# GD32E53x register map
File version: 1.0
CPU: CM33 r0p4, little endian, MPU, FPU, 4 interrupt priority bits
Registers are 32-bit, read-write, reset 0x0 unless marked. A register's access mark holds for its fields unless they carry their own. Offsets are from the block's base; [hi:lo] are bit positions; {n}, {i} and the like mark numbered series.

## RCU — Reset and clock unit
Base 0x40021000
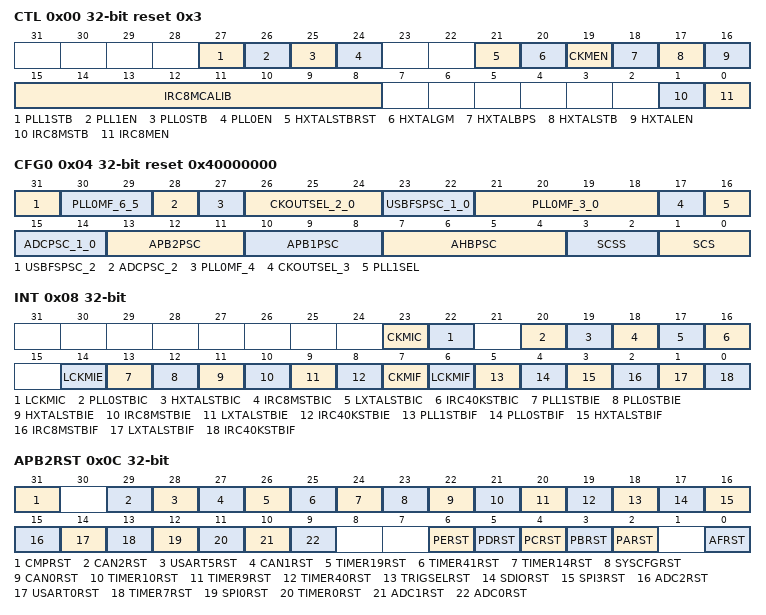
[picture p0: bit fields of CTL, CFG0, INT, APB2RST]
0x00 CTL access per field reset 0x3 — Control register
  [27] PLL1STB ro — PLL1 clock stabilization flag
  [26] PLL1EN rw — PLL1 enable
  [25] PLL0STB ro — PLL0 clock stabilization flag
  [24] PLL0EN rw — PLL0 enable
  [21] HXTALSTBRST rw — Reset HXTALSTB bit.
  [20] HXTALGM rw — HXTAL gm control
  [19] CKMEN rw — HXTAL clock monitor enable
  [18] HXTALBPS rw — High speed crystal oscillator (HXTAL) clock bypass mode enable
  [17] HXTALSTB ro — High speed crystal oscillator (HXTAL) clock stabilization flag
  [16] HXTALEN rw — High speed crystal oscillator (HXTAL) Enable
  [15:8] IRC8MCALIB ro — Internal 8MHz RC oscillator calibration value register
  [1] IRC8MSTB ro — IRC8M internal 8MHz RC oscillator stabilization flag
  [0] IRC8MEN rw — Internal 8MHz RC oscillator enable
0x04 CFG0 access per field reset 0x40000000 — Clock configuration register 0
  [31] USBFSPSC_2 rw — Bit 2 of USBFSPSC
  [30:29] PLL0MF_6_5 rw — Bit 6 and Bit 5 of PLL0MF
  [28] ADCPSC_2 rw — Bit 2 of ADCPSC
  [27] PLL0MF_4 rw — Bit 4 of PLL0MF
  [26:24] CKOUTSEL_2_0 rw — CKOUT clock source selection
  [23:22] USBFSPSC_1_0 rw — USBFS clock prescaler selection
  [21:18] PLL0MF_3_0 rw — The PLL0 clock multiplication factor
  [17] CKOUTSEL_3 rw — Bit 3 of CKOUTSEL
  [16] PLL1SEL rw — PLL1 clock source selection
  [15:14] ADCPSC_1_0 rw — ADC clock prescaler selection
  [13:11] APB2PSC rw — APB2 prescaler selection
  [10:8] APB1PSC rw — APB1 prescaler selection
  [7:4] AHBPSC rw — AHB prescaler selection
  [3:2] SCSS ro — System clock switch status
  [1:0] SCS rw — System clock switch
0x08 INT access per field — Clock interrupt register
  [23] CKMIC wo — HXTAL clock stuck interrupt clear
  [22] LCKMIC wo — LXTAL clock stuck interrupt clear
  [20] PLL0STBIC wo — PLL0 stabilization interrupt clear
  [19] HXTALSTBIC wo — HXTAL stabilization interrupt clear
  [18] IRC8MSTBIC wo — IRC8M stabilization interrupt clear
  [17] LXTALSTBIC wo — LXTAL stabilization interrupt clear
  [16] IRC40KSTBIC wo — IRC40K stabilization interrupt clear
  [14] LCKMIE rw — LXTAL clock stuck interrupt enable
  [13] PLL1STBIE rw — PLL1 stabilization interrupt enable
  [12] PLL0STBIE rw — PLL0 stabilization interrupt enable
  [11] HXTALSTBIE rw — HXTAL stabilization interrupt enable
  [10] IRC8MSTBIE rw — IRC8M stabilization interrupt enable
  [9] LXTALSTBIE rw — LXTAL stabilization interrupt enable
  [8] IRC40KSTBIE rw — IRC40K stabilization interrupt enable
  [7] CKMIF ro — HXTAL clock stuck interrupt flag
  [6] LCKMIF ro — LXTAL clock stuck interrupt flag
  [5] PLL1STBIF ro — PLL1 stabilization interrupt flag
  [4] PLL0STBIF ro — PLL0 stabilization interrupt flag
  [3] HXTALSTBIF ro — HXTAL stabilization interrupt flag
  [2] IRC8MSTBIF ro — IRC8M stabilization interrupt flag
  [1] LXTALSTBIF ro — LXTAL stabilization interrupt flag
  [0] IRC40KSTBIF ro — IRC40K stabilization interrupt flag
0x0C APB2RST — APB2 reset register
  [31] CMPRST — CMP reset
  [29] CAN2RST — CAN2 reset
  [28] USART5RST — USART5 reset
  [27] CAN1RST — CAN1 reset
  [26] TIMER19RST — TIMER19 reset
  [25] TIMER41RST — TIMER41 reset
  [24] TIMER14RST — TIMER14 reset
  [23] SYSCFGRST — SYSCFG reset
  [22] CAN0RST — CAN0 reset
  [21] TIMER10RST — TIMER10 reset
  [20] TIMER9RST — TIMER9 reset
  [19] TIMER40RST — TIMER40 reset
  [18] TRIGSELRST — TRIGSEL reset
  [17] SDIORST — SDIO reset
  [16] SPI3RST — SPI3 reset
  [15] ADC2RST — ADC2 reset
  [14] USART0RST — USART0 reset
  [13] TIMER7RST — TIMER7 reset
  [12] SPI0RST — SPI0 reset
  [11] TIMER0RST — TIMER0 reset
  [10] ADC1RST — ADC1 reset
  [9] ADC0RST — ADC0 reset
  [6] PERST — GPIOE reset
  [5] PDRST — GPIOD reset
  [4] PCRST — GPIOC reset
  [3] PBRST — GPIOB reset
  [2] PARST — GPIOA reset
  [0] AFRST — AFIO reset
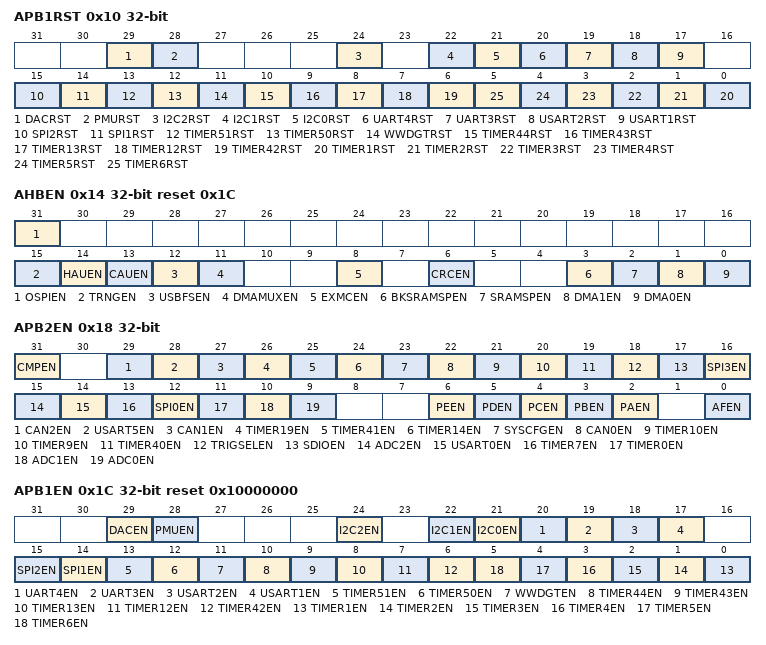
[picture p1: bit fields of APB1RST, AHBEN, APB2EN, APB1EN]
0x10 APB1RST — APB1 reset register
  [29] DACRST — DAC reset
  [28] PMURST — PMU reset
  [24] I2C2RST — I2C2 reset
  [22] I2C1RST — I2C1 reset
  [21] I2C0RST — I2C0 reset
  [20] UART4RST — UART4 reset
  [19] UART3RST — UART3 reset
  [18] USART2RST — USART2 reset
  [17] USART1RST — USART1 reset
  [15] SPI2RST — SPI2 reset
  [14] SPI1RST — SPI1 reset
  [13] TIMER51RST — TIMER51 reset
  [12] TIMER50RST — TIMER50 reset
  [11] WWDGTRST — WWDGT reset
  [10] TIMER44RST — TIMER44 reset
  [9] TIMER43RST — TIMER43 reset
  [8] TIMER13RST — TIMER13 reset
  [7] TIMER12RST — TIMER12 reset
  [6] TIMER42RST — TIMER42 reset
  [n-1] TIMER{n}RST (n=1..6) — TIMER{n} reset
0x14 AHBEN reset 0x1C — AHB enable register
  [31] OSPIEN — OSPI clock enable
  [15] TRNGEN — TRNG clock enable
  [14] HAUEN — HAU clock enable
  [13] CAUEN — CAU clock enable
  [12] USBFSEN — USBFS clock enable
  [11] DMAMUXEN — DMAMUX clock enable
  [8] EXMCEN — EXMC clock enable
  [6] CRCEN — CRC clock enable
  [3] BKSRAMSPEN — Back up SRAM clock enable when sleep mode
  [2] SRAMSPEN — SRAM interface clock enable when sleep mode
  [1] DMA1EN — DMA1 clock enable
  [0] DMA0EN — DMA0 clock enable
0x18 APB2EN — APB2 enable register
  [31] CMPEN — CMP clock enable
  [29] CAN2EN — CAN2 clock enable
  [28] USART5EN — USART5 clock enable
  [27] CAN1EN — CAN1 clock enable
  [26] TIMER19EN — TIMER19 clock enable
  [25] TIMER41EN — TIMER41 clock enable
  [24] TIMER14EN — TIMER14 clock enable
  [23] SYSCFGEN — SYSCFG clock enable
  [22] CAN0EN — CAN0 clock enable
  [21] TIMER10EN — TIMER10 clock enable
  [20] TIMER9EN — TIMER9 clock enable
  [19] TIMER40EN — TIMER40 clock enable
  [18] TRIGSELEN — TRIGSEL clock enable
  [17] SDIOEN — SDIO clock enable
  [16] SPI3EN — SPI3 clock enable
  [15] ADC2EN — ADC2 clock enable
  [14] USART0EN — USART0 clock enable
  [13] TIMER7EN — TIMER7 clock enable
  [12] SPI0EN — SPI0 clock enable
  [11] TIMER0EN — TIMER0 clock enable
  [10] ADC1EN — ADC1 clock enable
  [9] ADC0EN — ADC0 clock enable
  [6] PEEN — GPIO port E clock enable
  [5] PDEN — GPIO port D clock enable
  [4] PCEN — GPIO port C clock enable
  [3] PBEN — GPIO port B clock enable
  [2] PAEN — GPIO port A clock enable
  [0] AFEN — Alternate function IO clock enable
0x1C APB1EN reset 0x10000000 — APB1 enable register
  [29] DACEN — DAC clock enable
  [28] PMUEN — PMU clock enable
  [24] I2C2EN — I2C2 clock enable
  [22] I2C1EN — I2C1 clock enable
  [21] I2C0EN — I2C0 clock enable
  [20] UART4EN — UART4 clock enable
  [19] UART3EN — UART3 clock enable
  [18] USART2EN — USART2 clock enable
  [17] USART1EN — USART1 clock enable
  [15] SPI2EN — SPI2 clock enable
  [14] SPI1EN — SPI1 clock enable
  [13] TIMER51EN — TIMER51 clock enable
  [12] TIMER50EN — TIMER50 clock enable
  [11] WWDGTEN — WWDGT clock enable
  [10] TIMER44EN — TIMER44 clock enable
  [9] TIMER43EN — TIMER43 clock enable
  [8] TIMER13EN — TIMER13 clock enable
  [7] TIMER12EN — TIMER12 clock enable
  [6] TIMER42EN — TIMER42 clock enable
  [n-1] TIMER{n}EN (n=1..6) — TIMER{n} clock enable
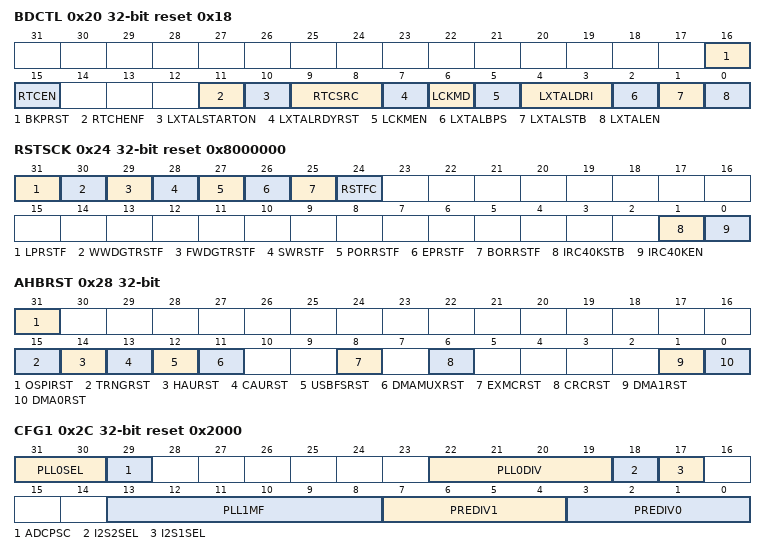
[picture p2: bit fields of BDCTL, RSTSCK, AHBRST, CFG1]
0x20 BDCTL access per field reset 0x18 — Backup domain control register
  [16] BKPRST rw — Backup domain reset
  [15] RTCEN rw — RTC clock enable
  [11] RTCHENF ro — RTC high frequency clock enable flag
  [10] LXTALSTARTON rw — LXTAL start circuit on control
  [9:8] RTCSRC rw — RTC clock entry selection
  [7] LXTALRDYRST rw — LXTAL ready reset
  [6] LCKMD ro — LXTAL clock failure detection
  [5] LCKMEN rw — LXTAL clock monitor enable
  [4:3] LXTALDRI rw — LXTAL drive capability
  [2] LXTALBPS rw — LXTAL bypass mode enable
  [1] LXTALSTB ro — Low speed crystal oscillator stabilization flag
  [0] LXTALEN rw — LXTAL enable
0x24 RSTSCK access per field reset 0x8000000 — Reset source/clock register
  [31] LPRSTF ro — Low-power reset flag
  [30] WWDGTRSTF ro — Window watchdog timer reset flag
  [29] FWDGTRSTF ro — Free watchdog timer reset flag
  [28] SWRSTF ro — Software reset flag
  [27] PORRSTF ro — Power reset flag
  [26] EPRSTF ro — External pin reset flag
  [25] BORRSTF ro — BOR reset flag
  [24] RSTFC rw — Reset flag clear
  [1] IRC40KSTB ro — IRC40K stabilization flag
  [0] IRC40KEN rw — IRC40K enable
0x28 AHBRST — AHB reset register
  [31] OSPIRST — OSPI reset
  [15] TRNGRST — TRNG reset
  [14] HAURST — HAU reset
  [13] CAURST — CAU reset
  [12] USBFSRST — USBFS reset
  [11] DMAMUXRST — DMAMUX reset
  [8] EXMCRST — EXMC reset
  [6] CRCRST — CRC reset
  [1] DMA1RST — DMA0 reset
  [0] DMA0RST — DMA1 reset
0x2C CFG1 reset 0x2000 — Clock configuration register 1
  [31:30] PLL0SEL — PLL0 clock source selection
  [29] ADCPSC — Bit 4 of ADCPSC
  [22:19] PLL0DIV — PLL0 divider
  [18] I2S2SEL — I2S2 Clock Source Selection
  [17] I2S1SEL — I2S1 Clock Source Selection
  [13:8] PLL1MF — The PLL1 clock multiplication factor
  [7:4] PREDIV1 — PREDIV1 division factor.
  [3:0] PREDIV0 — PREDIV0 division factor.
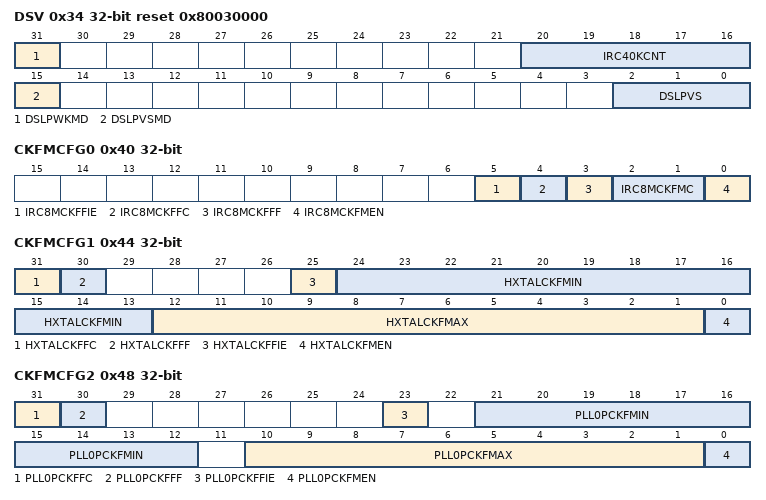
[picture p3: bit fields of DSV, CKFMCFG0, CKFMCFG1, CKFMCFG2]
0x34 DSV reset 0x80030000 — Deep-sleep mode voltage register
  [31] DSLPWKMD — Deepsleep wake-up method.
  [20:16] IRC40KCNT — After DeepSleep wake-up, the startup waiting time is forced to be configured as 3
  [15] DSLPVSMD — Deep sleep mode voltage selection mode
  [2:0] DSLPVS — Deep sleep mode voltage selection
0x40 CKFMCFG0 access per field — Clock frequency monitor configuration register 0
  [5] IRC8MCKFFIE rw — IRC8M clock frequency failure interrupt enable
  [4] IRC8MCKFFC wo — IRC8M clock frequency failure flag clear
  [3] IRC8MCKFFF ro — IRC8M clock frequency failure flag
  [2:1] IRC8MCKFMC rw — IRC8M clock frequency monitor configuration
  [0] IRC8MCKFMEN rw — IRC8M clock frequency monitor enable
0x44 CKFMCFG1 access per field — Clock frequency monitor configuration register 1
  [31] HXTALCKFFC wo — HXTAL clock frequency failure flag clear
  [30] HXTALCKFFF ro — HXTAL clock frequency failure flag
  [25] HXTALCKFFIE rw — HXTAL clock frequency failure interrupt enable
  [24:13] HXTALCKFMIN rw — HXTAL clock frequency monitor configuration minimum value
  [12:1] HXTALCKFMAX rw — HXTAL clock frequency monitor configuration maximum value
  [0] HXTALCKFMEN rw — HXTAL clock frequency monitor enable
0x48 CKFMCFG2 access per field — Clock frequency monitor configuration register 2
  [31] PLL0PCKFFC wo — PLL0P clock frequency failure flag clear
  [30] PLL0PCKFFF ro — PLL0P clock frequency failure flag
  [23] PLL0PCKFFIE rw — PLL0P clock frequency failure interrupt enable
  [21:12] PLL0PCKFMIN rw — PLL0P clock frequency monitor configuration minimum value
  [10:1] PLL0PCKFMAX rw — PLL0P clock frequency monitor configuration maximum value
  [0] PLL0PCKFMEN rw — PLL0P clock frequency monitor enable
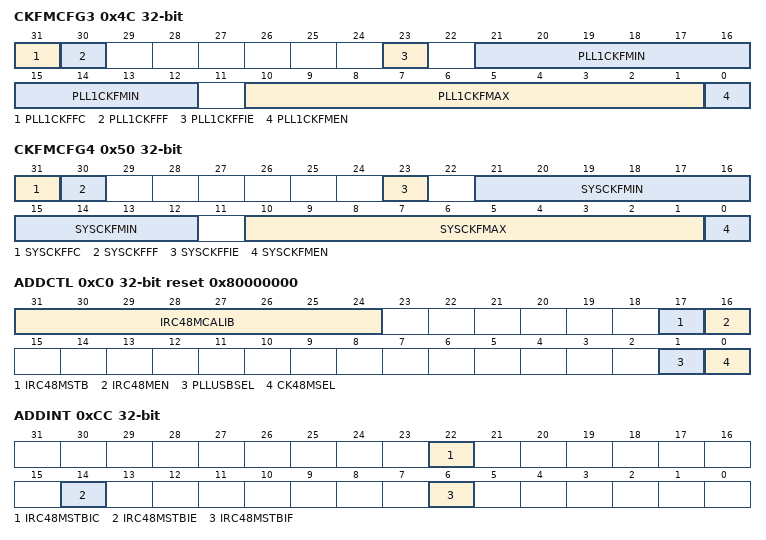
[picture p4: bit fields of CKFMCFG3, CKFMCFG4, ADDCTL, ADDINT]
0x4C CKFMCFG3 access per field — Clock frequency monitor configuration register 3
  [31] PLL1CKFFC wo — PLL1 clock frequency failure flag clear
  [30] PLL1CKFFF ro — PLL1 clock frequency failure flag
  [23] PLL1CKFFIE rw — PLL1 clock frequency failure interrupt enable
  [21:12] PLL1CKFMIN rw — PLL1 clock frequency monitor configuration minimum value
  [10:1] PLL1CKFMAX rw — PLL1 clock frequency monitor configuration maximum value
  [0] PLL1CKFMEN rw — PLL1 clock frequency monitor enable
0x50 CKFMCFG4 access per field — Clock frequency monitor configuration register 4
  [31] SYSCKFFC wo — SYSCLK clock frequency failure flag clear
  [30] SYSCKFFF ro — SYSCLK clock frequency failure flag
  [23] SYSCKFFIE rw — SYSCLK clock frequency failure interrupt enable
  [21:12] SYSCKFMIN rw — SYSCLK clock frequency monitor configuration minimum value
  [10:1] SYSCKFMAX rw — SYSCLK clock frequency monitor configuration maximum value
  [0] SYSCKFMEN rw — SYSCLK clock frequency monitor enable
0xC0 ADDCTL access per field reset 0x80000000 — Additional clock control register
  [31:24] IRC48MCALIB ro — Internal 48MHz RC oscillator calibration value register
  [17] IRC48MSTB ro — Internal 48MHz RC oscillator clock stabilization flag
  [16] IRC48MEN rw — Internal 48MHz RC oscillator enable
  [1] PLLUSBSEL rw — PLLUSB clock source selection
  [0] CK48MSEL rw — 48MHz clock selection
0xCC ADDINT access per field — Additional clock interrupt register
  [22] IRC48MSTBIC wo — Internal 48 MHz RC oscillator stabilization interrupt clear
  [14] IRC48MSTBIE rw — Internal 48 MHz RC oscillator stabilization interrupt enable
  [6] IRC48MSTBIF ro — IRC48M stabilization interrupt flag
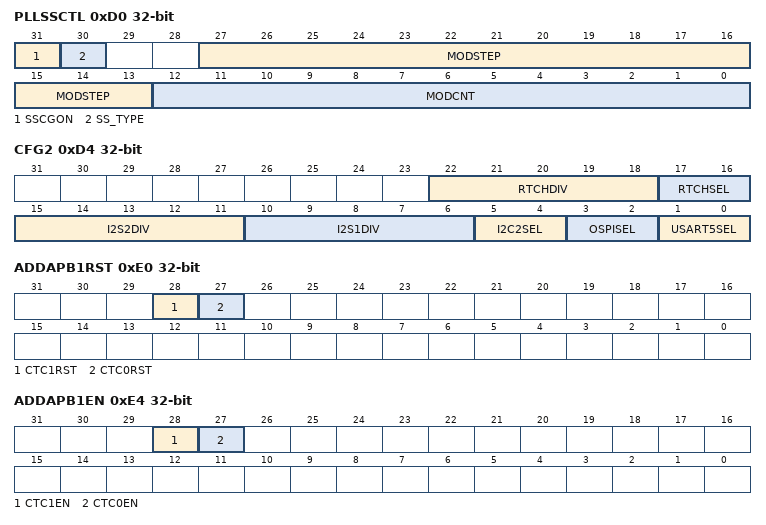
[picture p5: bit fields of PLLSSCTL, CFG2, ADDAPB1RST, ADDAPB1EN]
0xD0 PLLSSCTL — PLL clock spread spectrum control register
  [31] SSCGON — PLL0 spread spectrum modulation enable
  [30] SS_TYPE — PLL0 spread spectrum modulation type select
  [27:13] MODSTEP — These bits configure PLL0 spread spectrum modulation profile amplitude and frequency.
  [12:0] MODCNT — These bits configure PLL0 spread spectrum modulation profile amplitude and frequency.
0xD4 CFG2 — Clock configuration register 2
  [22:18] RTCHDIV — RTCH divider
  [17:16] RTCHSEL — RTCH clock source selection
  [15:11] I2S2DIV — I2S2DIV divider
  [10:6] I2S1DIV — I2S1DIV divider
  [5:4] I2C2SEL — I2C2 Clock Source Selection
  [3:2] OSPISEL — OSPI clock source selection
  [1:0] USART5SEL — USART5 clock source selection
0xE0 ADDAPB1RST — APB1 additional reset register
  [28] CTC1RST — CTC1 reset
  [27] CTC0RST — CTC0 reset
0xE4 ADDAPB1EN — APB1 additional enable register
  [28] CTC1EN — CTC1 clock enable
  [27] CTC0EN — CTC0 clock enable
0x100 LOCK
  [31] LOCK — RCU register lock bit
